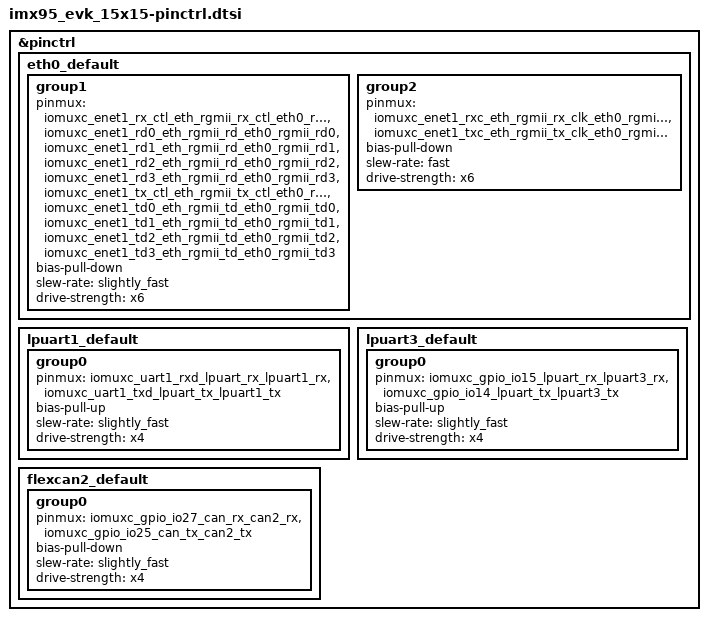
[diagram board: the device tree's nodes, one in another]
/*
 * Copyright 2025 NXP
 * SPDX-License-Identifier: Apache-2.0
 */

#include <nxp/nxp_imx/mimx9596cvtxn-pinctrl.dtsi>

&pinctrl {
	eth0_default: eth0_default {
		group1 {
			pinmux = <&iomuxc_enet1_rx_ctl_eth_rgmii_rx_ctl_eth0_rgmii_rx_ctl>,
				<&iomuxc_enet1_rd0_eth_rgmii_rd_eth0_rgmii_rd0>,
				<&iomuxc_enet1_rd1_eth_rgmii_rd_eth0_rgmii_rd1>,
				<&iomuxc_enet1_rd2_eth_rgmii_rd_eth0_rgmii_rd2>,
				<&iomuxc_enet1_rd3_eth_rgmii_rd_eth0_rgmii_rd3>,
				<&iomuxc_enet1_tx_ctl_eth_rgmii_tx_ctl_eth0_rgmii_tx_ctl>,
				<&iomuxc_enet1_td0_eth_rgmii_td_eth0_rgmii_td0>,
				<&iomuxc_enet1_td1_eth_rgmii_td_eth0_rgmii_td1>,
				<&iomuxc_enet1_td2_eth_rgmii_td_eth0_rgmii_td2>,
				<&iomuxc_enet1_td3_eth_rgmii_td_eth0_rgmii_td3>;
			bias-pull-down;
			slew-rate = "slightly_fast";
			drive-strength = "x6";
		};
		group2 {
			pinmux = <&iomuxc_enet1_rxc_eth_rgmii_rx_clk_eth0_rgmii_rx_clk>,
				<&iomuxc_enet1_txc_eth_rgmii_tx_clk_eth0_rgmii_tx_clk>;
			bias-pull-down;
			slew-rate = "fast";
			drive-strength = "x6";
		};
	};

	lpuart1_default: lpuart1_default {
		group0 {
			pinmux = <&iomuxc_uart1_rxd_lpuart_rx_lpuart1_rx>,
				 <&iomuxc_uart1_txd_lpuart_tx_lpuart1_tx>;
			bias-pull-up;
			slew-rate = "slightly_fast";
			drive-strength = "x4";
		};
	};

	lpuart3_default: lpuart3_default {
		group0 {
			pinmux = <&iomuxc_gpio_io15_lpuart_rx_lpuart3_rx>,
				 <&iomuxc_gpio_io14_lpuart_tx_lpuart3_tx>;
			bias-pull-up;
			slew-rate = "slightly_fast";
			drive-strength = "x4";
		};
	};

	flexcan2_default: flexcan2_default {
		group0 {
			pinmux = <&iomuxc_gpio_io27_can_rx_can2_rx>,
				<&iomuxc_gpio_io25_can_tx_can2_tx>;
			bias-pull-down;
			slew-rate = "slightly_fast";
			drive-strength = "x4";
		};
	};
};
